# MIMXRT1061 register map
Vendor: nxp.com; File version: 1.0
CPU: CM7 r0p1, little endian, MPU, FPU, VTOR, 4 interrupt priority bits
Registers are 32-bit, read-write, reset 0x0 unless marked. A register's access mark holds for its fields unless they carry their own. Offsets are from the block's base; [hi:lo] are bit positions; {n}, {i} and the like mark numbered series; 'fields as' and 'values as' point back to an identical list.

## OCOTP
Base 0x401F4000
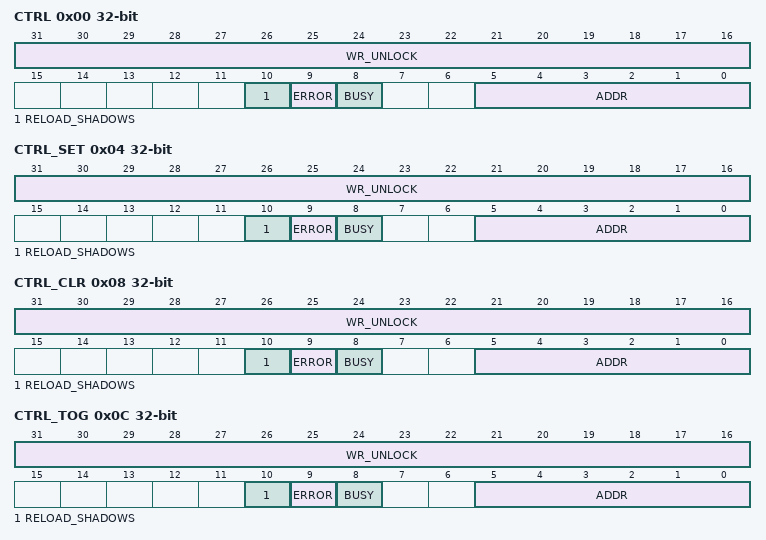
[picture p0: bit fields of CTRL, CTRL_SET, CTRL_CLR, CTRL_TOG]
0x00 CTRL — OTP Controller Control and Status Register
  [31:16] WR_UNLOCK — Write Unlock
    0=NO_KEY (OTP write access is locked.); 0x3E77=KEY (OTP write access is unlocked.)
  [10] RELOAD_SHADOWS — Reload Shadow Registers
    0=SHADOW_NOFORCE_RELOAD (Do not force shadow register re-load.); 1=SHADOW_FORCE_RELOAD (Force shadow register re-load. This bit is cleared automatically after shadow registers are re-loaded.)
  [9] ERROR — Locked Region Access Error
    0=NO_ERROR; 1=ERROR (Error - access to a locked region requested.)
  [8] BUSY ro — OTP controller status bit
    0=NOT_BUSY (No write or read access to OTP started.); 1=BUSY (Write or read access to OTP started.)
  [5:0] ADDR — OTP write and read access address register
0x04 CTRL_SET write-1-sets — OTP Controller Control and Status Register
  [31:16] WR_UNLOCK write-1-sets — Write Unlock
  [10] RELOAD_SHADOWS write-1-sets — Reload Shadow Registers
  [9] ERROR write-1-sets — Locked Region Access Error
  [8] BUSY ro write-1-sets — OTP controller status bit
  [5:0] ADDR write-1-sets — OTP write and read access address register
0x08 CTRL_CLR write-1-clears — OTP Controller Control and Status Register
  [31:16] WR_UNLOCK write-1-clears — Write Unlock
  [10] RELOAD_SHADOWS write-1-clears — Reload Shadow Registers
  [9] ERROR write-1-clears — Locked Region Access Error
  [8] BUSY ro write-1-clears — OTP controller status bit
  [5:0] ADDR write-1-clears — OTP write and read access address register
0x0C CTRL_TOG write-1-toggles — OTP Controller Control and Status Register
  [31:16] WR_UNLOCK write-1-toggles — Write Unlock
  [10] RELOAD_SHADOWS write-1-toggles — Reload Shadow Registers
  [9] ERROR write-1-toggles — Locked Region Access Error
  [8] BUSY ro write-1-toggles — OTP controller status bit
  [5:0] ADDR write-1-toggles — OTP write and read access address register
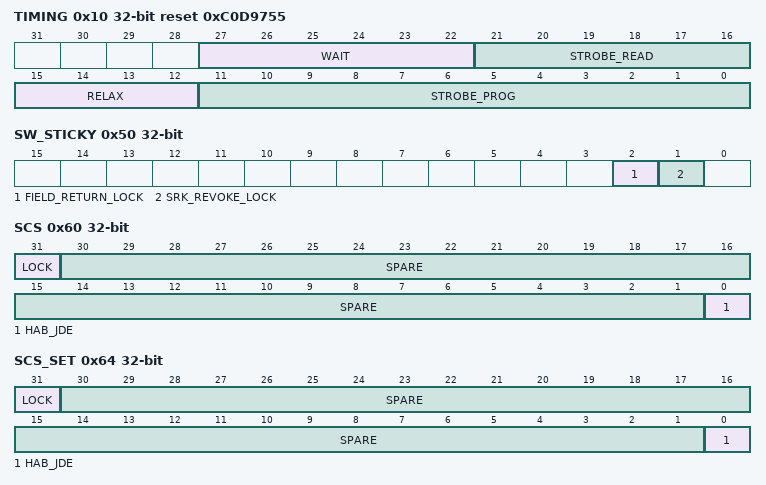
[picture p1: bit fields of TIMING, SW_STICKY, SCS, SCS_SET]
0x10 TIMING reset 0xC0D9755 — OTP Controller Timing Register
  [27:22] WAIT — Wait Interval
  [21:16] STROBE_READ — Read Strobe Period
  [15:12] RELAX — Relax Count Value
  [11:0] STROBE_PROG — Write Strobe Period
0x20 DATA — OTP Controller Write Data Register
  [31:0] DATA — Used to initiate a write to OTP. See the section for operating details.
0x30 READ_CTRL — OTP Controller Write Data Register
  [0] READ_FUSE
0x40 READ_FUSE_DATA — OTP Controller Read Data Register
  [31:0] DATA — The data read from OTP. See the section for operating details.
0x50 SW_STICKY — Sticky bit Register
  [2] FIELD_RETURN_LOCK
    0=notblocked (Writing to this region's shadow register and OTP fuse word are not blocked.); 1=blocked (Writing to this region's shadow register and OTP fuse word are blocked. Once this bit is set, it is always high unless a POR is issued.)
  [1] SRK_REVOKE_LOCK
    0=notblocked (The writing of this region's shadow register and OTP fuse word are not blocked.); 1=blocked (The writing of this region's shadow register and OTP fuse word are blocked. Once this bit is set, it is always high unless a POR is issued.)
0x60 SCS — Software Controllable Signals Register
  [31] LOCK
    0=unlocked (Bits in this register are unlocked.); 1=locked (Bits in this register are locked. When set, all of the bits in this register are locked and can not be changed through SW programming. After this bit is set, it can only be cleared by a POR.)
  [30:1] SPARE — Unallocated read/write bits for implementation specific software use.
  [0] HAB_JDE — HAB JTAG Debug Enable
    0=jtag_dbg_dis (JTAG debugging is not enabled by the HAB (it may still be enabled by other mechanisms).); 1=jtag_dbg_en (JTAG debugging is enabled by the HAB (though this signal may be gated off).)
0x64 SCS_SET write-1-sets — Software Controllable Signals Register
  [31] LOCK write-1-sets
  [30:1] SPARE write-1-sets — Unallocated read/write bits for implementation specific software use.
  [0] HAB_JDE write-1-sets — HAB JTAG Debug Enable
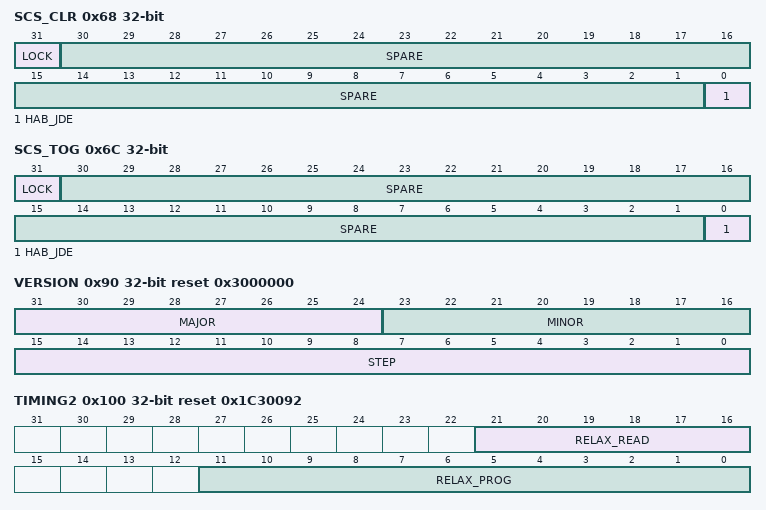
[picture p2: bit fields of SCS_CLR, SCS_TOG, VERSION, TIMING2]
0x68 SCS_CLR write-1-clears — Software Controllable Signals Register
  [31] LOCK write-1-clears
  [30:1] SPARE write-1-clears — Unallocated read/write bits for implementation specific software use.
  [0] HAB_JDE write-1-clears — HAB JTAG Debug Enable
0x6C SCS_TOG write-1-toggles — Software Controllable Signals Register
  [31] LOCK write-1-toggles
  [30:1] SPARE write-1-toggles — Unallocated read/write bits for implementation specific software use.
  [0] HAB_JDE write-1-toggles — HAB JTAG Debug Enable
0x90 VERSION ro reset 0x3000000 — OTP Controller Version Register
  [31:24] MAJOR — Major RTL Version
  [23:16] MINOR — Minor RTL Version
  [15:0] STEP — RTL Version Steping
0x100 TIMING2 reset 0x1C30092 — OTP Controller Timing Register 2
  [21:16] RELAX_READ — Relax Read count value
  [11:0] RELAX_PROG — Relax Prog. count value
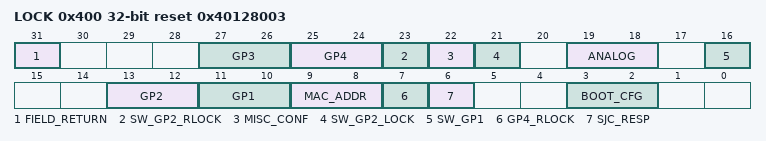
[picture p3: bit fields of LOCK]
0x400 LOCK reset 0x40128003 — Value of OTP Bank0 Word0 (Lock controls)
  [31] FIELD_RETURN — FIELD RETURN Status
    0=functional (The device is a functional part.); 1=field_returned (The device is a field returned part.)
  [27:26] GP3 ro — GP3 Write Lock Status
  [25:24] GP4 ro — GP4 Write Lock Status
  [23] SW_GP2_RLOCK ro — SW_GP2 Read Lock Status
    0=notblocked (The reading of this region's shadow register and OTP fuse word are not blocked.); 1=blocked (When set, the reading of this region's shadow register and OTP fuse word are blocked.)
  [22] MISC_CONF ro — MISC_CONF Write Lock Status
    0=notblocked (Writing of this region's shadow register and OTP fuse word are not blocked.); 1=blocked (When set, the writing of this region's shadow register and OTP fuse word are blocked.)
  [21] SW_GP2_LOCK ro — SW_GP2 Write Lock Status
    values as MISC_CONF
  [19:18] ANALOG ro — ANALOG Write Lock Status
  [16] SW_GP1 ro — SW_GP1 Write Lock Status
    values as MISC_CONF
  [13:12] GP2 ro — GP2 Write Lock Status
  [11:10] GP1 ro — GP1 Write Lock Status
  [9:8] MAC_ADDR ro — MAC_ADDR Write Lock Status
  [7] GP4_RLOCK ro — GP4 Read Lock Status
    0=notblocked (Reading of this region's shadow register and OTP fuse word are not blocked.); 1=blocked (When set, the reading of this region's shadow register and OTP fuse word are blocked.)
  [6] SJC_RESP ro — SJC_RESP Lock Status
    0=notblocked (The writing or reading of this region's shadow register and OTP fuse word are not blocked.); 1=blocked (When set, the writing of this region's shadow register and OTP fuse word are blocked. The read of this region's shadow register and OTP fuse word are also blocked)
  [3:2] BOOT_CFG ro — BOOT_CFG Write Lock Status
{0x410+0x10*i} CFG{i} (i=0..6) — Value of OTP Bank0 Word{i+1} (Configuration and Manufacturing Info.)
  [31:0] BITS
{0x480+0x10*i} MEM{i} (i=0..4) — Value of OTP Bank1 Word{i} (Memory Related Info.)
  [31:0] BITS
{0x4D0+0x10*i} ANA{i} (i=0..2) — Value of OTP Bank1 Word{i+5} (Analog Info.)
  [31:0] BITS
{0x580+0x10*i} SRK{i} (i=0..7) — Shadow Register for OTP Bank3 Word{i} (SRK Hash)
  [31:0] BITS
0x600 SJC_RESP0 — Value of OTP Bank4 Word0 (Secure JTAG Response Field)
  [31:0] BITS
0x610 SJC_RESP1 — Value of OTP Bank4 Word1 (Secure JTAG Response Field)
  [31:0] BITS
0x620 MAC0 — Value of OTP Bank4 Word2 (MAC Address)
  [31:0] BITS
0x630 MAC1 — Value of OTP Bank4 Word3 (MAC Address)
  [31:0] BITS
0x640 MAC2 — Value of OTP Bank4 Word4 (MAC2 Address)
  [31:0] BITS
0x660 GP1 — Value of OTP Bank4 Word6 (General Purpose Customer Defined Info)
  [31:0] BITS
0x670 GP2 — Value of OTP Bank4 Word7 (General Purpose Customer Defined Info)
  [31:0] BITS
0x680 SW_GP1 — Value of OTP Bank5 Word0 (SW GP1)
  [31:0] BITS
{0x550+0x10*i} SW_GP{i} (i=20..23) — Value of OTP Bank5 Word{i-19} (SW GP2)
  [31:0] BITS
0x6D0 MISC_CONF0 — Value of OTP Bank5 Word5 (Misc Conf)
  [31:0] BITS
0x6E0 MISC_CONF1 — Value of OTP Bank5 Word6 (Misc Conf)
  [31:0] BITS
0x6F0 SRK_REVOKE — Value of OTP Bank5 Word7 (SRK Revoke)
  [31:0] BITS
{0x6A0+0x10*i} GP{i} (i=30..33) — Value of OTP Bank7 Word{i-30} (GP3)
  [31:0] BITS
{0x640+0x10*i} GP{i} (i=40..43) — Value of OTP Bank7 Word{i-36} (GP4)
  [31:0] BITS
